# DEBUGSS_WRAP_CSTPIU_CFG_0_000720004000h register map
Vendor: Texas Instruments
Peripheral module from a debugger description file (folder am62L).
Registers are 32-bit, read-only, reset 0x0 unless marked. A register's access mark holds for its fields unless they carry their own. Offsets are as the file gives them; lines under a group give offsets from that group; [hi:lo] are bit positions; {n}, {i} and the like mark numbered series; 'fields as' and 'values as' point back to an identical list; <NAME> marks a mode.

## cstpiu_cfg_0
0x00 cstpiu_cfg_0_SUPPORTSIZE — This register indicates how many trace pins are available for export. One pin per bit, right justified
  [31:0] SUPPORTSIZEREG — This register indicates how many trace pins are available for export One pin per bit, right justified
0x04 cstpiu_cfg_0_CURPORTSIZE rw — The Current Port Size Register has the same format as the Supported Port Sizes register but only one bit is set, and all others must be zero
  [31:0] CURRENTPORTSIZE
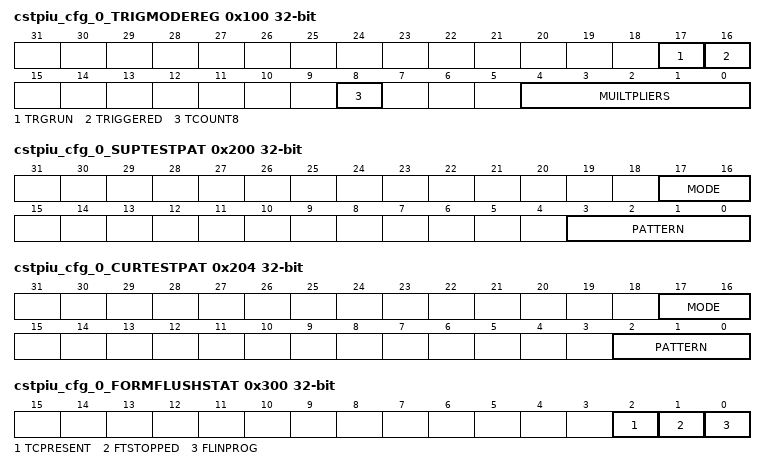
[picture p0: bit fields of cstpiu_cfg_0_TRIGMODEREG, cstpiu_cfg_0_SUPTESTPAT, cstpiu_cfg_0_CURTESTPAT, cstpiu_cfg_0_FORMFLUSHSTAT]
0x100 cstpiu_cfg_0_TRIGMODEREG — This register indicates the implemented Trigger Counter multipliers and other supported features of the trigger system
  [17] TRGRUN — Trigger Counter running A trigger has occurred but the counter is not at zero
  [16] TRIGGERED — A trigger has occurred and the counter has reached zero
  [8] TCOUNT8 — An 8-bit wide counter register implemented
  [4:0] MUILTPLIERS — Multiply the Trigger Counter by 2, 4, 16, 256, 64K supported Each bit is a mpy value
0x104 cstpiu_cfg_0_TRIGCTRREG access per field
  [7:0] TRIGCOUNT rw — 8-bit counter value for the number of words to be output from the formatter before a trigger is inserted
0x108 cstpiu_cfg_0_TRIGMPYREG access per field
  [4:0] MULTIPLIER rw — Trigger multiply value bit0=x2, bit1=x4, bit2=x16, bit3=x256, bit4=x64K
0x200 cstpiu_cfg_0_SUPTESTPAT — This register displays the supported patterns and modes for calibration
  [17:16] MODE — bit 16 is Timed Mode, bit 17 is continuous mode
  [3:0] PATTERN — bit0=Walking 1 pattern, bit1=walking 0, bit2=AA/55 pattern, bit3=FF/00 pattern
0x204 cstpiu_cfg_0_CURTESTPAT access per field — This register displays the supported patterns and modes for calibration
  [17:16] MODE rw — Select the Pattern Timer Mode, see Supported Patterns reg
  [2:0] PATTERN rw — Select the pattern to run, set Supported Patterns Reg
0x208 cstpiu_cfg_0_TESTPATCNT access per field — This register displays the supported patterns and modes for calibration
  [7:0] PATTERNCOUNT rw — Number of clocks a pattern should run before going to the next pattern
0x300 cstpiu_cfg_0_FORMFLUSHSTAT — This register displays the supported patterns and modes for calibration
  [2] TCPRESENT — If this bit is set then TRACECTL is present If no TRACECTL pin is present, then the data formatter must be used and only in continuous mode
  [1] FTSTOPPED — Formatter stopped The formatter has received a stop request signal and all trace data and post-amble has been output
  [0] FLINPROG — Flush In Progress This is an indication of the current state of AFVALIDS
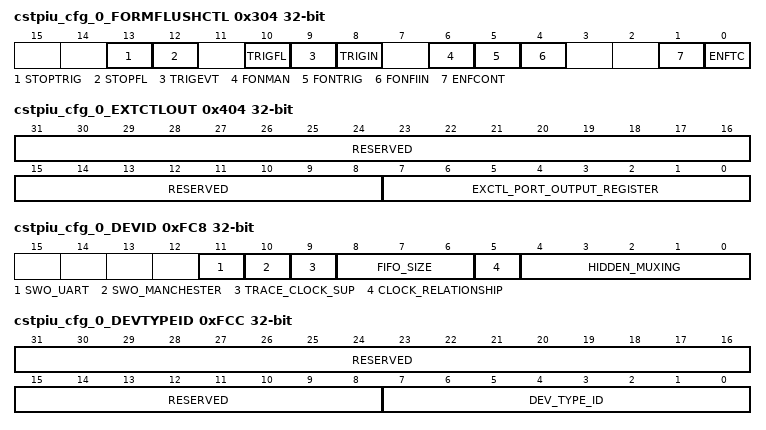
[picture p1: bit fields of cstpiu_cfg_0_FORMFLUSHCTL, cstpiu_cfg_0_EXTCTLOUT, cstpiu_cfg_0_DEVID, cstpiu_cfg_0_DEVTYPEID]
0x304 cstpiu_cfg_0_FORMFLUSHCTL access per field — This register controls the generation of stop, trigger, and flush events.
  [13] STOPTRIG rw — Stop the formatter after a Trigger Event is observed
  [12] STOPFL rw — Stop the formatter after a flush completes [return of AFREADYS]
  [10] TRIGFL rw — Indicates a trigger on Flush completion on AFREADYS being returned
  [9] TRIGEVT rw — Indicate a trigger on a Trigger Event
  [8] TRIGIN rw — Indicate a trigger on TRIGIN being asserted
  [6] FONMAN rw — Manually generate a flush of the system It is cleared when this flush has been serviced
  [5] FONTRIG rw — Generate flush using Trigger event
  [4] FONFIIN rw — Generate flush using the FLUSHIN interface
  [1] ENFCONT rw — Continuous Formatting Embed in trigger packets and indicate null cycles using Sync packets
  [0] ENFTC rw — Enable Formatting Do not embed Triggers into the formatted stream
0x308 cstpiu_cfg_0_FORMSYNCCTR access per field — This counter is the number of formatter frames since the last synchronization packet of 128 bits, and is a 12-bit counter with a maximum count value of 4096
  [11:0] CYCCOUNT rw — 12-bit counter value to indicate the number of complete frames between full sync packets
0x400 cstpiu_cfg_0_EXTCTLIN access per field — This register inputs data from an external port (if used)
  [7:0] EXCTL_PORT_INPUT_REGISTER ro
0x404 cstpiu_cfg_0_EXTCTLOUT rw — This register is output to an external port (if used)
  [31:8] RESERVED — returns 0
  [7:0] EXCTL_PORT_OUTPUT_REGISTER
0xEE4 cstpiu_cfg_0_ITTRFLINACK access per field — Integration Test Trigger In and Flush In Acknowledge.
  [1:0] ATID rw — Writing this register sets the value of ATIDM Reading it returns the value of ATIDS
0xEE8 cstpiu_cfg_0_ITTRFLIN rw — Integration Test Trigger In and Flush In Register.
  [31:0] INTEGRATIONTRFLIN
0xEEC cstpiu_cfg_0_ITATBDATA0 rw — Integration Test ATB Data Register 0
  [31:0] INTEGRATION_TEST_ATB_REG
0xEF0 cstpiu_cfg_0_ITATBCTR2 rw — Integration Test ATB Control Register 2.
  [31:0] INTEGRATION_TEST_ATB_CTL_REG2
0xEF4 cstpiu_cfg_0_ITATBCTR1 rw — Integration Test ATB Control Register 1.
  [31:0] INTEGRATION_TEST_ATB_CTL_REG1
0xEF8 cstpiu_cfg_0_ITATBCTR0 rw — Integration Test ATB Control Register 0
  [31:0] INTEGRATION_TEST_ATB_CTL_REG0
0xF00 cstpiu_cfg_0_INTCTRL access per field — Integration Mode Register
  [0] INTEGMODEN rw — Integration Mode Enable
0xFA0 cstpiu_cfg_0_CTSET access per field — Claim Tag Set Register
  [3:0] CLAIM_TAG_SET rw
0xFA4 cstpiu_cfg_0_CTCLR access per field — Claim Tag Clear Register
  [3:0] CLAIM_TAG_CLEAR rw
0xFB0 cstpiu_cfg_0_LAREG rw — Software must write 0xCSACCE55 to this register in order for application to gain access to the other registers. If paddrdbg31 is high, this is ignored.
  [31:0] LOCK_ACCESS_REGISTER
0xFB4 cstpiu_cfg_0_LSREG — The CTI implements two memory maps controlled through PADDRDBG31. When PADDRDBG31 is HIGH, the Lock Status Register reads as 0x0 indicating that no lock exists. When PADDRDBG31 is LOW, the Lock Status Register reads as 0x3 from reset. This indicates a 32-bit lock access mechanism is present and is locked
  [1:0] LOCK_STATUS — The CTI implements two memory maps controlled through PADDRDBG31 When PADDRDBG31 is HIGH, the Lock Status Register reads as 0x0 indicating that no lock exists When PADDRDBG31 is LOW, the Lock Status Register reads as 0x3 from reset This indicates a 32-bit lock access mechanism is present and is locked Application must write to the LAREG to gain access
0xFB8 cstpiu_cfg_0_AUTHST — Reports the required security level.
  [3:0] AUTHENTICATION_STATUS — Reports the required security level bit 0 indicates Invasive Debug Controlled and bit 1 is the current value Bit 2 indicates non-invasive debug controlled and bit 3 is the current value Returns 0x5
0xFC8 cstpiu_cfg_0_DEVID — This shows the characteristics of the TPIU
  [11] SWO_UART — Indicates Serial Wire Output [UART/NRZ] is not supported Defaul = 0
  [10] SWO_MANCHESTER — Indicates Serial Wire Output [Manchester] is not supported Default = 0
  [9] TRACE_CLOCK_SUP — Indicates trace clock + data is supported
  [8:6] FIFO_SIZE — FIFO size in powers of 2 A value of 2 gives a FIFO size of 4 entries, 16 bytes Default is3'b010
  [5] CLOCK_RELATIONSHIP — Indicates the relationship between ATCLK and TRACECLKIN 0x1 indicates asynchronous
  [4:0] HIDDEN_MUXING — When nonzero this value indicates the type/number of ATB multiplexing present on the input to the ATB Currently only 0x00 is supported, that is, no multiplexing present
0xFCC cstpiu_cfg_0_DEVTYPEID — Device Type Identifier Register
  [31:8] RESERVED — Reserveed, returns 0
  [7:0] DEV_TYPE_ID — Device Type Identifier
0xFD0 cstpiu_cfg_0_PERID4 — Peripheral ID4 Register
  [7:0] PERIPH_ID4 — Peripheral ID 4, returns 0x4
0xFE0 cstpiu_cfg_0_PERID0 — Peripheral ID0 Register
  [7:0] PERIPH_ID0 — Perpiheral ID 0, returns 0x06
0xFE4 cstpiu_cfg_0_PERID1 — Peripheral ID1 Register
  [7:0] PERIPH_ID1 — Peripheral ID 1, returns 0xB9
0xFE8 cstpiu_cfg_0_PERID2 — Peripheral ID2 Register
  [7:0] PERIPH_ID2 — Peripheral ID 2, returns 9x2B
0xFEC cstpiu_cfg_0_PERID3 — Peripheral ID3 Register
  [7:0] PERPIH_ID3 — Peripheral ID3 register, returns 0x00
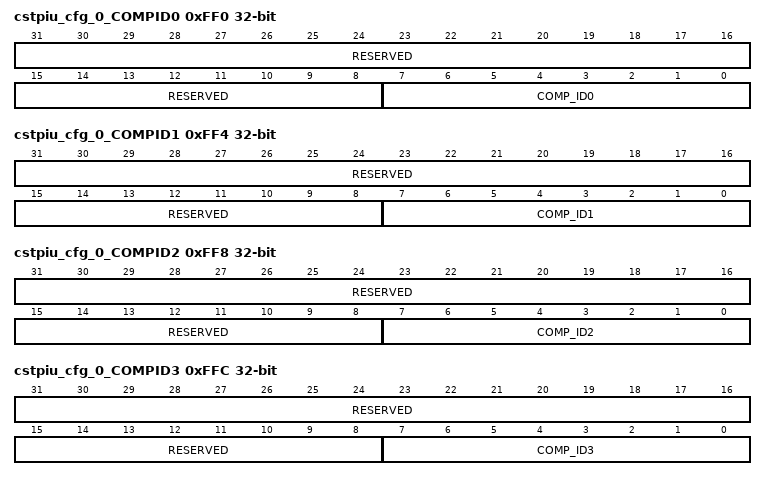
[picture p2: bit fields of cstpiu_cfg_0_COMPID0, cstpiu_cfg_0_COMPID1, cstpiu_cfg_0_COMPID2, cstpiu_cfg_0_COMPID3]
0xFF0 cstpiu_cfg_0_COMPID0 — Component ID0 Register
  [31:8] RESERVED — Read returns 0
  [7:0] COMP_ID0 — A component identification register, that indicates that the identification registers are present This register also indicates the component class
0xFF4 cstpiu_cfg_0_COMPID1 — Component ID1 Register
  [31:8] RESERVED — Read returns 0
  [7:0] COMP_ID1 — A component identification register, that indicates that the identification registers are present This register also indicates the component class
0xFF8 cstpiu_cfg_0_COMPID2 — Component ID2 Register
  [31:8] RESERVED — Returns 0
  [7:0] COMP_ID2 — A component identification register, that indicates that the identification registers are present This register also indicates the component class
0xFFC cstpiu_cfg_0_COMPID3 — Component ID3 Register
  [31:8] RESERVED — returns 0 when read
  [7:0] COMP_ID3 — A component identification register, that indicates that the identification registers are present This register also indicates the component class
